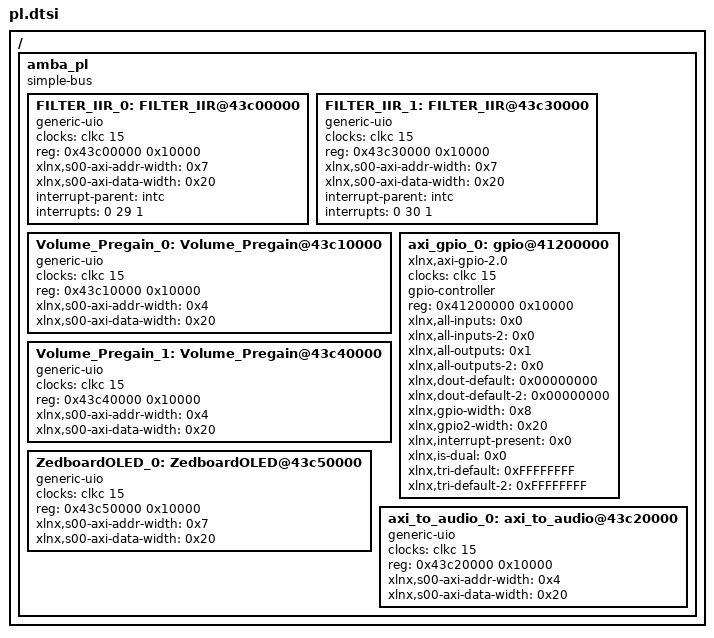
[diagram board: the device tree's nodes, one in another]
/*
 * CAUTION: This file is automatically generated by Xilinx.
 * Version: XSCT 2020.1.1
 * Today is: Tue Dec 14 19:52:15 2021
 */


/ {
	amba_pl: amba_pl {
		#address-cells = <1>;
		#size-cells = <1>;
		compatible = "simple-bus";
		ranges ;
		FILTER_IIR_0: FILTER_IIR@43c00000 {
			/* This is a place holder node for a custom IP, user may need to update the entries */
			clock-names = "s00_axi_aclk";
			clocks = <&clkc 15>;
			compatible = "generic-uio";
			reg = <0x43c00000 0x10000>;
			xlnx,s00-axi-addr-width = <0x7>;
			xlnx,s00-axi-data-width = <0x20>;
			interrupt-parent = <&intc>;
			interrupts = <0 29 1>;
		};
		FILTER_IIR_1: FILTER_IIR@43c30000 {
			/* This is a place holder node for a custom IP, user may need to update the entries */
			clock-names = "s00_axi_aclk";
			clocks = <&clkc 15>;
			compatible = "generic-uio";
			reg = <0x43c30000 0x10000>;
			xlnx,s00-axi-addr-width = <0x7>;
			xlnx,s00-axi-data-width = <0x20>;
			interrupt-parent = <&intc>;
			interrupts = <0 30 1>;
		};
		Volume_Pregain_0: Volume_Pregain@43c10000 {
			/* This is a place holder node for a custom IP, user may need to update the entries */
			clock-names = "s00_axi_aclk";
			clocks = <&clkc 15>;
			compatible = "generic-uio";
			reg = <0x43c10000 0x10000>;
			xlnx,s00-axi-addr-width = <0x4>;
			xlnx,s00-axi-data-width = <0x20>;
		};
		Volume_Pregain_1: Volume_Pregain@43c40000 {
			/* This is a place holder node for a custom IP, user may need to update the entries */
			clock-names = "s00_axi_aclk";
			clocks = <&clkc 15>;
			compatible = "generic-uio";
			reg = <0x43c40000 0x10000>;
			xlnx,s00-axi-addr-width = <0x4>;
			xlnx,s00-axi-data-width = <0x20>;
		};
		ZedboardOLED_0: ZedboardOLED@43c50000 {
			/* This is a place holder node for a custom IP, user may need to update the entries */
			clock-names = "s00_axi_aclk";
			clocks = <&clkc 15>;
			compatible = "generic-uio";
			reg = <0x43c50000 0x10000>;
			xlnx,s00-axi-addr-width = <0x7>;
			xlnx,s00-axi-data-width = <0x20>;
		};
		axi_gpio_0: gpio@41200000 {
			#gpio-cells = <3>;
			clock-names = "s_axi_aclk";
			clocks = <&clkc 15>;
			compatible = "xlnx,axi-gpio-2.0", "xlnx,xps-gpio-1.00.a", "generic-uio";
			gpio-controller ;
			reg = <0x41200000 0x10000>;
			xlnx,all-inputs = <0x0>;
			xlnx,all-inputs-2 = <0x0>;
			xlnx,all-outputs = <0x1>;
			xlnx,all-outputs-2 = <0x0>;
			xlnx,dout-default = <0x00000000>;
			xlnx,dout-default-2 = <0x00000000>;
			xlnx,gpio-width = <0x8>;
			xlnx,gpio2-width = <0x20>;
			xlnx,interrupt-present = <0x0>;
			xlnx,is-dual = <0x0>;
			xlnx,tri-default = <0xFFFFFFFF>;
			xlnx,tri-default-2 = <0xFFFFFFFF>;
		};
		axi_to_audio_0: axi_to_audio@43c20000 {
			/* This is a place holder node for a custom IP, user may need to update the entries */
			clock-names = "s00_axi_aclk";
			clocks = <&clkc 15>;
			compatible = "generic-uio";
			reg = <0x43c20000 0x10000>;
			xlnx,s00-axi-addr-width = <0x4>;
			xlnx,s00-axi-data-width = <0x20>;
		};
	};
};
